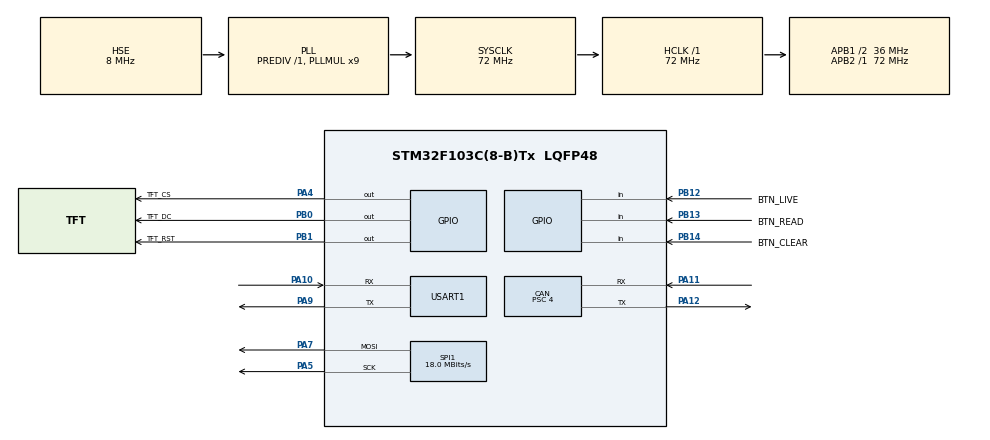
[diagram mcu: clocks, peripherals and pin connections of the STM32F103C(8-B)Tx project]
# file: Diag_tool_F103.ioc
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CAN.BS1=CAN_BS1_15TQ
CAN.BS2=CAN_BS2_2TQ
CAN.CalculateBaudRate=500000
CAN.CalculateTimeBit=2000
CAN.CalculateTimeQuantum=111.11111111111111
CAN.Prescaler=4
Dma.Request0=SPI1_TX
Dma.SPI1_TX.0.Direction=DMA_MEMORY_TO_PERIPH
Dma.SPI1_TX.0.Instance=DMA1_Channel3
Dma.SPI1_TX.0.MemDataAlignment=DMA_MDATAALIGN_BYTE
Dma.SPI1_TX.0.MemInc=DMA_MINC_ENABLE
Dma.SPI1_TX.0.Mode=DMA_NORMAL
Dma.SPI1_TX.0.PeriphDataAlignment=DMA_PDATAALIGN_BYTE
Dma.SPI1_TX.0.PeriphInc=DMA_PINC_DISABLE
Dma.SPI1_TX.0.Priority=DMA_PRIORITY_LOW
IWDG.Prescaler=IWDG_PRESCALER_32
IWDG.Reload=625
Mcu.Family=STM32F1
Mcu.Name=STM32F103C(8-B)Tx
Mcu.Package=LQFP48
NVIC.CAN1_RX1_IRQn=true\:0\:0\:false\:false\:true\:true\:true\:true
NVIC.DMA1_Channel3_IRQn=true\:0\:0\:false\:false\:true\:false\:true\:true
NVIC.PriorityGroup=NVIC_PRIORITYGROUP_4
PA10.Mode=Asynchronous
PA10.Signal=USART1_RX
PA11.Mode=CAN_Activate
PA11.Signal=CAN_RX
PA12.Mode=CAN_Activate
PA12.Signal=CAN_TX
PA4.GPIO_Label=TFT_CS
PA4.GPIO_Speed=GPIO_SPEED_FREQ_HIGH
PA4.PinState=GPIO_PIN_SET
PA4.Signal=GPIO_Output
PA5.Mode=TX_Only_Simplex_Unidirect_Master
PA5.Signal=SPI1_SCK
PA7.Mode=TX_Only_Simplex_Unidirect_Master
PA7.Signal=SPI1_MOSI
PA9.Mode=Asynchronous
PA9.Signal=USART1_TX
PB0.GPIO_Label=TFT_DC
PB0.PinState=GPIO_PIN_RESET
PB0.Signal=GPIO_Output
PB1.GPIO_Label=TFT_RST
PB1.PinState=GPIO_PIN_SET
PB1.Signal=GPIO_Output
PB12.GPIO_Label=BTN_LIVE
PB12.GPIO_PuPd=GPIO_PULLUP
PB12.Signal=GPIO_Input
PB13.GPIO_Label=BTN_READ
PB13.GPIO_PuPd=GPIO_PULLUP
PB13.Signal=GPIO_Input
PB14.GPIO_Label=BTN_CLEAR
PB14.GPIO_PuPd=GPIO_PULLUP
PB14.Signal=GPIO_Input
PD0-OSC_IN.Mode=HSE-External-Oscillator
PD0-OSC_IN.Signal=RCC_OSC_IN
PD1-OSC_OUT.Mode=HSE-External-Oscillator
PD1-OSC_OUT.Signal=RCC_OSC_OUT
ProjectManager.HeapSize=0x200
ProjectManager.StackSize=0x400
ProjectManager.TargetToolchain=STM32CubeIDE
RCC.AHBFreq_Value=72000000
RCC.APB1CLKDivider=RCC_HCLK_DIV2
RCC.APB1Freq_Value=36000000
RCC.APB1TimFreq_Value=72000000
RCC.APB2Freq_Value=72000000
RCC.APB2TimFreq_Value=72000000
RCC.HCLKFreq_Value=72000000
RCC.PLLMUL=RCC_PLL_MUL9
RCC.PLLSourceVirtual=RCC_PLLSOURCE_HSE
RCC.SYSCLKFreq_VALUE=72000000
RCC.SYSCLKSource=RCC_SYSCLKSOURCE_PLLCLK
RCC.USBFreq_Value=72000000
SPI1.BaudRatePrescaler=SPI_BAUDRATEPRESCALER_4
SPI1.CalculateBaudRate=18.0 MBits/s
SPI1.Direction=SPI_DIRECTION_2LINES
SPI1.Mode=SPI_MODE_MASTER
SPI1.VirtualType=VM_MASTER
USART1.VirtualMode=VM_ASYNC
VP_IWDG_VS_IWDG.Mode=IWDG_Activate
VP_SYS_VS_ND.Mode=No_Debug
board=custom

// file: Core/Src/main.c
/* USER CODE BEGIN Header */
/**
  ******************************************************************************
  * @file           : main.c
  * @brief          : Main program body
  ******************************************************************************
  * @attention
  *
  * Copyright (c) 2026 STMicroelectronics.
  * All rights reserved.
  *
  * This software is licensed under terms that can be found in the LICENSE file
  * in the root directory of this software component.
  * If no LICENSE file comes with this software, it is provided AS-IS.
  *
  ******************************************************************************
  */
/* USER CODE END Header */
#include "main.h"

/* USER CODE BEGIN Includes */
#include "diag_app.h"
/* USER CODE END Includes */

CAN_HandleTypeDef hcan;

IWDG_HandleTypeDef hiwdg;

SPI_HandleTypeDef hspi1;
DMA_HandleTypeDef hdma_spi1_tx;

UART_HandleTypeDef huart1;

void SystemClock_Config(void);
static void MX_GPIO_Init(void);
static void MX_DMA_Init(void);
static void MX_CAN_Init(void);
static void MX_IWDG_Init(void);
static void MX_SPI1_Init(void);
static void MX_USART1_UART_Init(void);

int main(void)
{

  /* MCU Configuration--------------------------------------------------------*/

  /* Reset of all peripherals, Initializes the Flash interface and the Systick. */
  HAL_Init();

  /* Configure the system clock */
  SystemClock_Config();

  /* Initialize all configured peripherals */
  MX_GPIO_Init();
  MX_DMA_Init();
  MX_CAN_Init();
  MX_IWDG_Init();
  MX_SPI1_Init();
  MX_USART1_UART_Init();
  /* USER CODE BEGIN 2 */
  diag_setup();
  /* USER CODE END 2 */

  /* Infinite loop */
  while (1)
  {

    /* USER CODE BEGIN 3 */
	  diag_loop();
  }
  /* USER CODE END 3 */
}

void SystemClock_Config(void)
{
  RCC_OscInitTypeDef RCC_OscInitStruct = {0};
  RCC_ClkInitTypeDef RCC_ClkInitStruct = {0};

  /** Initializes the RCC Oscillators according to the specified parameters
  * in the RCC_OscInitTypeDef structure.
  */
  RCC_OscInitStruct.OscillatorType = RCC_OSCILLATORTYPE_LSI|RCC_OSCILLATORTYPE_HSE;
  RCC_OscInitStruct.HSEState = RCC_HSE_ON;
  RCC_OscInitStruct.HSEPredivValue = RCC_HSE_PREDIV_DIV1;
  RCC_OscInitStruct.HSIState = RCC_HSI_ON;
  RCC_OscInitStruct.LSIState = RCC_LSI_ON;
  RCC_OscInitStruct.PLL.PLLState = RCC_PLL_ON;
  RCC_OscInitStruct.PLL.PLLSource = RCC_PLLSOURCE_HSE;
  RCC_OscInitStruct.PLL.PLLMUL = RCC_PLL_MUL9;
  if (HAL_RCC_OscConfig(&RCC_OscInitStruct) != HAL_OK)
  {
    Error_Handler();
  }

  /** Initializes the CPU, AHB and APB buses clocks
  */
  RCC_ClkInitStruct.ClockType = RCC_CLOCKTYPE_HCLK|RCC_CLOCKTYPE_SYSCLK
                              |RCC_CLOCKTYPE_PCLK1|RCC_CLOCKTYPE_PCLK2;
  RCC_ClkInitStruct.SYSCLKSource = RCC_SYSCLKSOURCE_PLLCLK;
  RCC_ClkInitStruct.AHBCLKDivider = RCC_SYSCLK_DIV1;
  RCC_ClkInitStruct.APB1CLKDivider = RCC_HCLK_DIV2;
  RCC_ClkInitStruct.APB2CLKDivider = RCC_HCLK_DIV1;

  if (HAL_RCC_ClockConfig(&RCC_ClkInitStruct, FLASH_LATENCY_2) != HAL_OK)
  {
    Error_Handler();
  }
}

static void MX_CAN_Init(void)
{

  hcan.Instance = CAN1;
  hcan.Init.Prescaler = 4;
  hcan.Init.Mode = CAN_MODE_NORMAL;
  hcan.Init.SyncJumpWidth = CAN_SJW_1TQ;
  hcan.Init.TimeSeg1 = CAN_BS1_15TQ;
  hcan.Init.TimeSeg2 = CAN_BS2_2TQ;
  hcan.Init.TimeTriggeredMode = DISABLE;
  hcan.Init.AutoBusOff = DISABLE;
  hcan.Init.AutoWakeUp = DISABLE;
  hcan.Init.AutoRetransmission = DISABLE;
  hcan.Init.ReceiveFifoLocked = DISABLE;
  hcan.Init.TransmitFifoPriority = DISABLE;
  if (HAL_CAN_Init(&hcan) != HAL_OK)
  {
    Error_Handler();
  }

}

static void MX_IWDG_Init(void)
{

  hiwdg.Instance = IWDG;
  hiwdg.Init.Prescaler = IWDG_PRESCALER_32;
  hiwdg.Init.Reload = 625;
  if (HAL_IWDG_Init(&hiwdg) != HAL_OK)
  {
    Error_Handler();
  }

}

static void MX_SPI1_Init(void)
{

  /* SPI1 parameter configuration*/
  hspi1.Instance = SPI1;
  hspi1.Init.Mode = SPI_MODE_MASTER;
  hspi1.Init.Direction = SPI_DIRECTION_2LINES;
  hspi1.Init.DataSize = SPI_DATASIZE_8BIT;
  hspi1.Init.CLKPolarity = SPI_POLARITY_LOW;
  hspi1.Init.CLKPhase = SPI_PHASE_1EDGE;
  hspi1.Init.NSS = SPI_NSS_SOFT;
  hspi1.Init.BaudRatePrescaler = SPI_BAUDRATEPRESCALER_4;
  hspi1.Init.FirstBit = SPI_FIRSTBIT_MSB;
  hspi1.Init.TIMode = SPI_TIMODE_DISABLE;
  hspi1.Init.CRCCalculation = SPI_CRCCALCULATION_DISABLE;
  hspi1.Init.CRCPolynomial = 10;
  if (HAL_SPI_Init(&hspi1) != HAL_OK)
  {
    Error_Handler();
  }

}

static void MX_USART1_UART_Init(void)
{

  huart1.Instance = USART1;
  huart1.Init.BaudRate = 115200;
  huart1.Init.WordLength = UART_WORDLENGTH_8B;
  huart1.Init.StopBits = UART_STOPBITS_1;
  huart1.Init.Parity = UART_PARITY_NONE;
  huart1.Init.Mode = UART_MODE_TX_RX;
  huart1.Init.HwFlowCtl = UART_HWCONTROL_NONE;
  huart1.Init.OverSampling = UART_OVERSAMPLING_16;
  if (HAL_UART_Init(&huart1) != HAL_OK)
  {
    Error_Handler();
  }

}

static void MX_DMA_Init(void)
{

  /* DMA controller clock enable */
  __HAL_RCC_DMA1_CLK_ENABLE();

  /* DMA interrupt init */
  /* DMA1_Channel3_IRQn interrupt configuration */
  HAL_NVIC_SetPriority(DMA1_Channel3_IRQn, 0, 0);
  HAL_NVIC_EnableIRQ(DMA1_Channel3_IRQn);

}

static void MX_GPIO_Init(void)
{
  GPIO_InitTypeDef GPIO_InitStruct = {0};

  /* GPIO Ports Clock Enable */
  __HAL_RCC_GPIOD_CLK_ENABLE();
  __HAL_RCC_GPIOA_CLK_ENABLE();
  __HAL_RCC_GPIOB_CLK_ENABLE();

  /*Configure GPIO pin Output Level */
  HAL_GPIO_WritePin(TFT_CS_GPIO_Port, TFT_CS_Pin, GPIO_PIN_SET);

  /*Configure GPIO pin Output Level */
  HAL_GPIO_WritePin(TFT_DC_GPIO_Port, TFT_DC_Pin, GPIO_PIN_RESET);

  /*Configure GPIO pin Output Level */
  HAL_GPIO_WritePin(TFT_RST_GPIO_Port, TFT_RST_Pin, GPIO_PIN_SET);

  /*Configure GPIO pin : TFT_CS_Pin */
  GPIO_InitStruct.Pin = TFT_CS_Pin;
  GPIO_InitStruct.Mode = GPIO_MODE_OUTPUT_PP;
  GPIO_InitStruct.Pull = GPIO_NOPULL;
  GPIO_InitStruct.Speed = GPIO_SPEED_FREQ_HIGH;
  HAL_GPIO_Init(TFT_CS_GPIO_Port, &GPIO_InitStruct);

  /*Configure GPIO pins : TFT_DC_Pin TFT_RST_Pin */
  GPIO_InitStruct.Pin = TFT_DC_Pin|TFT_RST_Pin;
  GPIO_InitStruct.Mode = GPIO_MODE_OUTPUT_PP;
  GPIO_InitStruct.Pull = GPIO_NOPULL;
  GPIO_InitStruct.Speed = GPIO_SPEED_FREQ_LOW;
  HAL_GPIO_Init(GPIOB, &GPIO_InitStruct);

  /*Configure GPIO pins : BTN_LIVE_Pin BTN_READ_Pin BTN_CLEAR_Pin */
  GPIO_InitStruct.Pin = BTN_LIVE_Pin|BTN_READ_Pin|BTN_CLEAR_Pin;
  GPIO_InitStruct.Mode = GPIO_MODE_INPUT;
  GPIO_InitStruct.Pull = GPIO_PULLUP;
  HAL_GPIO_Init(GPIOB, &GPIO_InitStruct);

}

void Error_Handler(void)
{
  __disable_irq();
  while (1)
  {
  }
}
